VERSION ""

NS_ :

BS_:

BU_: XXX

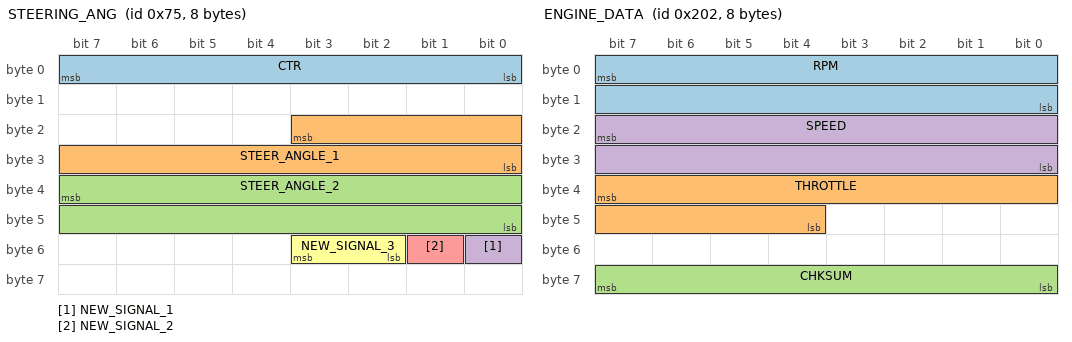
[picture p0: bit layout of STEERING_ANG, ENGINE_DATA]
BO_ 117 STEERING_ANG: 8 XXX
 SG_ CTR : 7|8@0+ (1,0) [0|255] "" XXX
 SG_ STEER_ANGLE_1 : 19|12@0+ (1,0) [0|255] "" XXX
 SG_ STEER_ANGLE_2 : 39|16@0+ (1,0) [0|131071] "" XXX
 SG_ NEW_SIGNAL_1 : 48|1@0+ (1,0) [0|1] "" XXX
 SG_ NEW_SIGNAL_2 : 49|1@0+ (1,0) [0|1] "" XXX
 SG_ NEW_SIGNAL_3 : 51|2@0+ (1,0) [0|63] "" XXX

BO_ 118 NEW_MSG_2: 8 XXX
 SG_ NEW_SIGNAL_2 : 19|12@0+ (1,0) [0|4095] "" XXX
 SG_ CTR : 7|8@0+ (1,0) [0|127] "" XXX

BO_ 514 ENGINE_DATA: 8 XXX
 SG_ RPM : 7|16@0+ (1,0) [0|65535] "" XXX
 SG_ THROTTLE : 39|12@0+ (1,0) [0|255] "" XXX
 SG_ CHKSUM : 56|8@1+ (1,0) [0|127] "" XXX
 SG_ SPEED : 23|16@0+ (0.01,0) [0|32767] "KPH" XXX

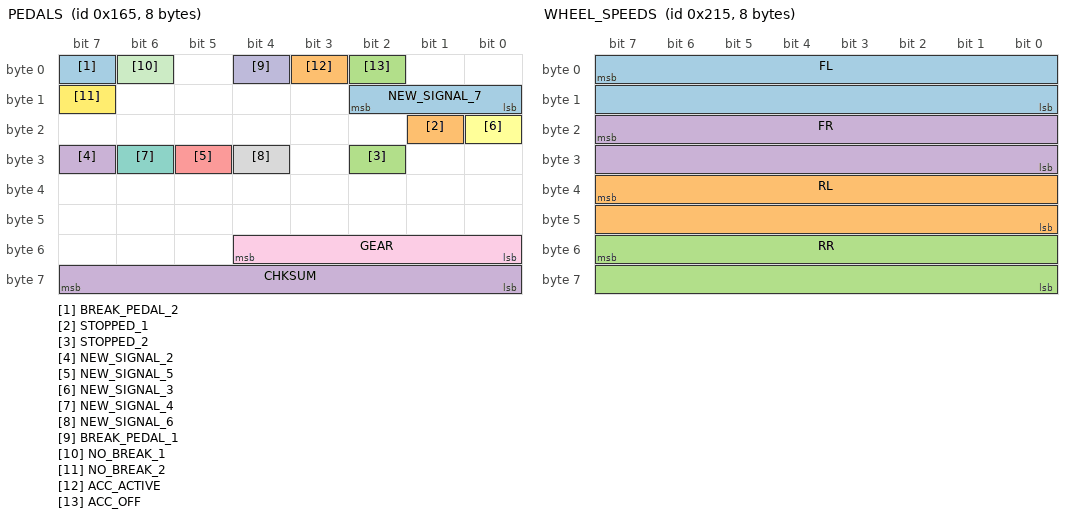
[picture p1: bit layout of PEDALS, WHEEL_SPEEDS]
BO_ 357 PEDALS: 8 XXX
 SG_ BREAK_PEDAL_2 : 7|1@1+ (1,0) [0|255] "" XXX
 SG_ STOPPED_1 : 17|1@0+ (1,0) [0|1] "" XXX
 SG_ STOPPED_2 : 26|1@0+ (1,0) [0|16777215] "" XXX
 SG_ NEW_SIGNAL_2 : 31|1@0+ (1,0) [0|15] "" XXX
 SG_ NEW_SIGNAL_5 : 29|1@0+ (1,0) [0|1] "" XXX
 SG_ NEW_SIGNAL_3 : 16|1@0+ (1,0) [0|3] "" XXX
 SG_ NEW_SIGNAL_4 : 30|1@0+ (1,0) [0|7] "" XXX
 SG_ NEW_SIGNAL_6 : 28|1@0+ (1,0) [0|1] "" XXX
 SG_ GEAR : 48|5@1+ (1,0) [0|255] "" XXX
 SG_ BREAK_PEDAL_1 : 4|1@0+ (1,0) [0|1] "" XXX
 SG_ NO_BREAK_1 : 6|1@0+ (1,0) [0|7] "" XXX
 SG_ NO_BREAK_2 : 15|1@0+ (1,0) [0|7] "" XXX
 SG_ NEW_SIGNAL_7 : 8|3@1+ (1,0) [0|7] "" XXX
 SG_ ACC_ACTIVE : 3|1@0+ (1,0) [0|1] "" XXX
 SG_ ACC_OFF : 2|1@1+ (1,0) [0|15] "" XXX
 SG_ CHKSUM : 63|8@0+ (1,0) [0|15] "" XXX

BO_ 533 WHEEL_SPEEDS: 8 XXX
 SG_ FL : 7|16@0+ (0.01,-100) [0|16383] "" XXX
 SG_ RL : 39|16@0+ (0.01,-100) [0|15] "" XXX
 SG_ RR : 55|16@0+ (0.01,-100) [0|65535] "" XXX
 SG_ FR : 23|16@0+ (0.01,-100) [0|65535] "" XXX

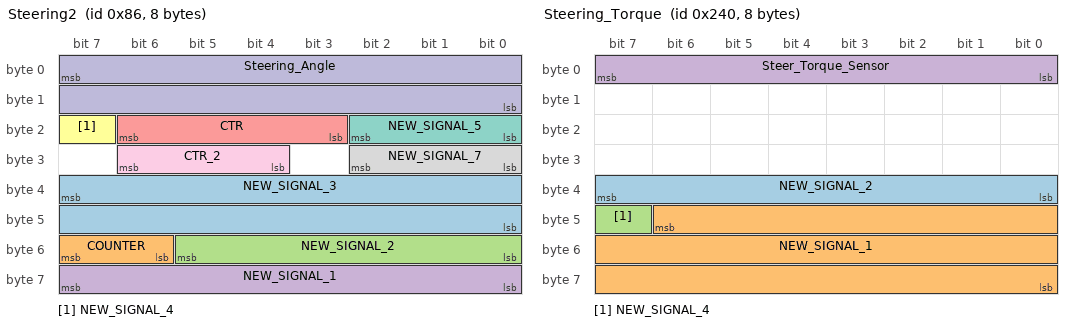
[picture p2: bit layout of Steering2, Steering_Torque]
BO_ 134 Steering2: 8 XXX
 SG_ NEW_SIGNAL_3 : 39|16@0+ (1,0) [0|15] "" XXX
 SG_ COUNTER : 55|2@0+ (1,0) [0|255] "" XXX
 SG_ NEW_SIGNAL_2 : 48|6@1+ (1,0) [0|7] "" XXX
 SG_ NEW_SIGNAL_1 : 63|8@0+ (1,0) [0|255] "" XXX
 SG_ CTR : 22|4@0+ (1,0) [0|7] "" XXX
 SG_ NEW_SIGNAL_4 : 23|1@0+ (1,0) [0|1] "" XXX
 SG_ NEW_SIGNAL_5 : 18|3@0+ (1,0) [0|1] "" XXX
 SG_ NEW_SIGNAL_7 : 24|3@1+ (1,0) [0|7] "" XXX
 SG_ CTR_2 : 28|3@1+ (1,0) [0|7] "" XXX
 SG_ Steering_Angle : 7|16@0+ (0.1,-1600) [-500|500] "deg" XXX

BO_ 576 Steering_Torque: 8 XXX
 SG_ NEW_SIGNAL_2 : 39|8@0+ (1,0) [0|127] "" XXX
 SG_ NEW_SIGNAL_1 : 46|23@0- (1,0) [0|255] "" XXX
 SG_ NEW_SIGNAL_4 : 47|1@0+ (1,0) [0|3] "" XXX
 SG_ Steer_Torque_Sensor : 0|8@1+ (1,0) [0|255] "" XXX

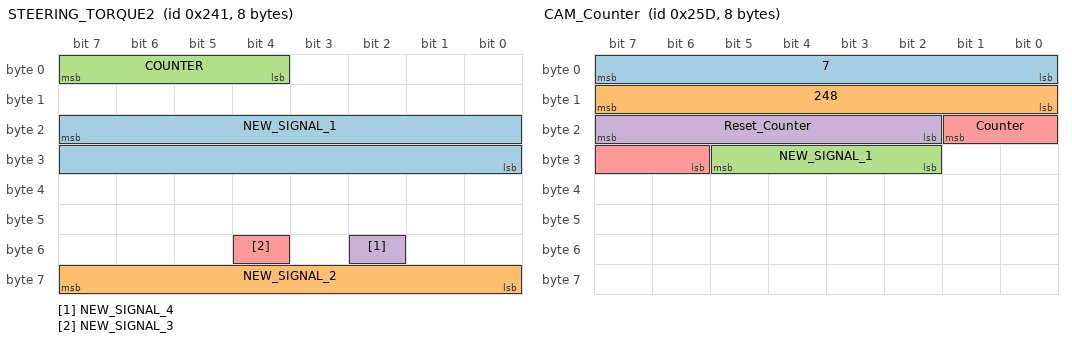
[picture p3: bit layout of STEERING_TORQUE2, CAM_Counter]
BO_ 577 STEERING_TORQUE2: 8 XXX
 SG_ NEW_SIGNAL_1 : 23|16@0+ (1,0) [0|1] "" XXX
 SG_ NEW_SIGNAL_2 : 63|8@0+ (1,0) [0|255] "" XXX
 SG_ COUNTER : 7|4@0+ (1,0) [0|15] "" XXX
 SG_ NEW_SIGNAL_4 : 50|1@1+ (1,0) [0|3] "" XXX
 SG_ NEW_SIGNAL_3 : 52|1@0+ (1,0) [0|3] "" XXX

BO_ 582 CAM__LANEINFO: 8 XXX
 SG_ Counter : 7|2@0+ (1,0) [0|3] "" XXX
 SG_ NEW_SIGNAL_4 : 40|8@1+ (1,0) [0|127] "" XXX
 SG_ NEW_SIGNAL_2 : 55|18@0+ (1,0) [0|65535] "" XXX
 SG_ NEW_SIGNAL_1 : 5|38@0- (1,0) [0|65535] "" XXX

BO_ 541 CAM__Empty: 8 XXX

BO_ 605 CAM_Counter: 8 XXX
 SG_ 7 : 0|8@1+ (1,0) [0|7] "" XXX
 SG_ 248 : 8|8@1+ (1,0) [0|255] "" XXX
 SG_ NEW_SIGNAL_1 : 26|4@1+ (1,0) [0|31] "" XXX
 SG_ Reset_Counter : 23|6@0+ (1,0) [0|63] "" XXX
 SG_ Counter : 17|4@0+ (1,0) [0|255] "" XXX

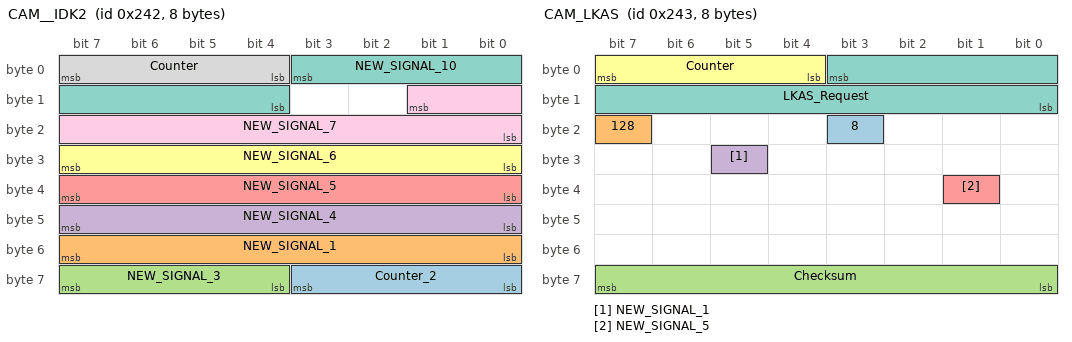
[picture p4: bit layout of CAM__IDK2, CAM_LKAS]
BO_ 578 CAM__IDK2: 8 XXX
 SG_ Counter_2 : 56|4@1+ (1,0) [0|15] "" XXX
 SG_ NEW_SIGNAL_1 : 48|8@1+ (1,0) [0|255] "" XXX
 SG_ NEW_SIGNAL_3 : 63|4@0+ (1,0) [0|255] "" XXX
 SG_ NEW_SIGNAL_4 : 40|8@1+ (1,0) [0|255] "" XXX
 SG_ NEW_SIGNAL_5 : 32|8@1+ (1,0) [0|255] "" XXX
 SG_ NEW_SIGNAL_6 : 24|8@1+ (1,0) [0|255] "" XXX
 SG_ NEW_SIGNAL_10 : 3|8@0+ (1,0) [0|1] "" XXX
 SG_ Counter : 7|4@0+ (1,0) [0|15] "" XXX
 SG_ NEW_SIGNAL_7 : 9|10@0+ (1,0) [0|255] "" XXX

BO_ 579 CAM_LKAS: 8 XXX
 SG_ 8 : 19|1@1+ (1,0) [0|8589934591] "" XXX
 SG_ 128 : 23|1@0+ (1,0) [0|3] "" XXX
 SG_ Checksum : 56|8@1+ (1,0) [0|15] "" XXX
 SG_ NEW_SIGNAL_1 : 29|1@0+ (1,0) [0|65535] "" XXX
 SG_ NEW_SIGNAL_5 : 33|1@1+ (1,0) [0|7] "" XXX
 SG_ Counter : 7|4@0+ (1,0) [0|3] "" XXX
 SG_ LKAS_Request : 3|12@0+ (1,-2048) [0|15] "" XXX

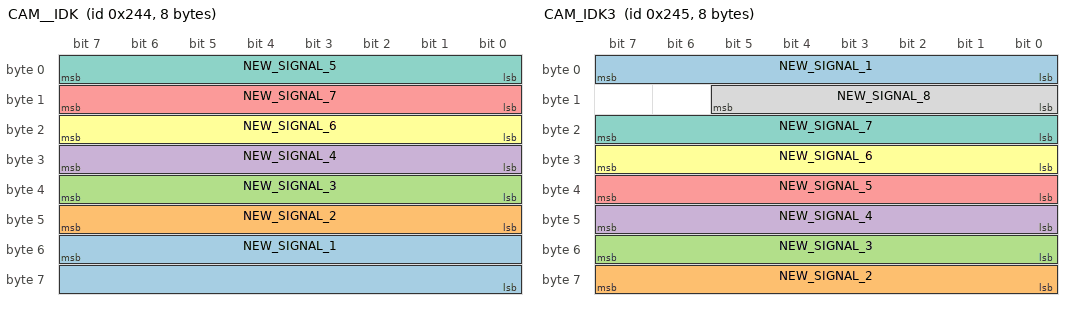
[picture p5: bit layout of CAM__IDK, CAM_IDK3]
BO_ 580 CAM__IDK: 8 XXX
 SG_ NEW_SIGNAL_1 : 55|16@0+ (1,0) [0|255] "" XXX
 SG_ NEW_SIGNAL_2 : 47|8@0+ (1,0) [0|65535] "" XXX
 SG_ NEW_SIGNAL_3 : 32|8@1+ (1,0) [0|255] "" XXX
 SG_ NEW_SIGNAL_4 : 24|8@1+ (1,0) [0|31] "" XXX
 SG_ NEW_SIGNAL_7 : 15|8@0+ (1,0) [0|1] "" XXX
 SG_ NEW_SIGNAL_6 : 16|8@1+ (1,0) [0|3] "" XXX
 SG_ NEW_SIGNAL_5 : 0|8@1+ (1,0) [0|127] "" XXX

BO_ 581 CAM_IDK3: 8 XXX
 SG_ NEW_SIGNAL_1 : 0|8@1+ (1,0) [0|15] "" XXX
 SG_ NEW_SIGNAL_2 : 56|8@1+ (1,0) [0|255] "" XXX
 SG_ NEW_SIGNAL_3 : 48|8@1+ (1,0) [0|255] "" XXX
 SG_ NEW_SIGNAL_4 : 40|8@1+ (1,0) [0|3] "" XXX
 SG_ NEW_SIGNAL_5 : 32|8@1+ (1,0) [0|255] "" XXX
 SG_ NEW_SIGNAL_6 : 24|8@1+ (1,0) [0|255] "" XXX
 SG_ NEW_SIGNAL_7 : 16|8@1+ (1,0) [0|15] "" XXX
 SG_ NEW_SIGNAL_8 : 8|6@1+ (1,0) [0|255] "" XXX

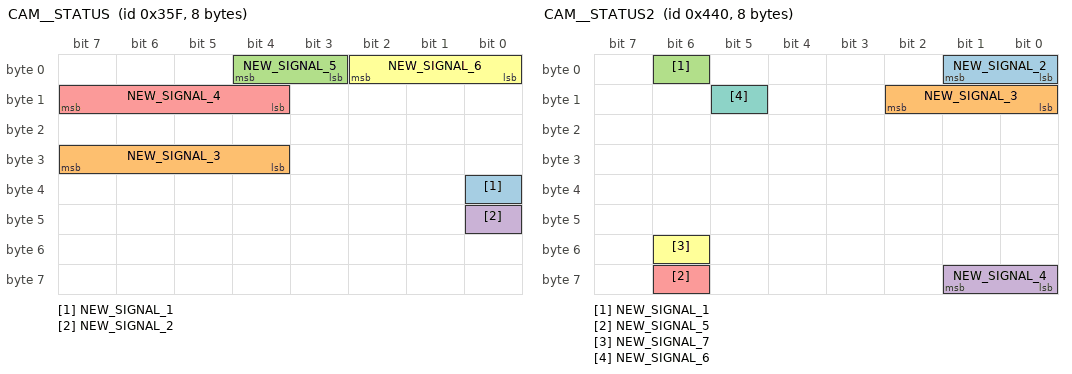
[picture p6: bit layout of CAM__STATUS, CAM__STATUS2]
BO_ 863 CAM__STATUS: 8 XXX
 SG_ NEW_SIGNAL_1 : 32|1@0+ (1,0) [0|32767] "" XXX
 SG_ NEW_SIGNAL_3 : 31|4@0+ (1,0) [0|1] "" XXX
 SG_ NEW_SIGNAL_5 : 4|2@0+ (1,0) [0|32767] "" XXX
 SG_ NEW_SIGNAL_2 : 40|1@1+ (1,0) [0|7] "" XXX
 SG_ NEW_SIGNAL_4 : 15|4@0+ (1,0) [0|15] "" XXX
 SG_ NEW_SIGNAL_6 : 0|3@1+ (1,0) [0|7] "" XXX

BO_ 1157 CAM__Empty2: 8 XXX

BO_ 1160 CAM__Empty3: 8 XXX
 SG_ NEW_SIGNAL_1 : 47|24@0+ (1,0) [0|16777215] "" XXX

BO_ 1088 CAM__STATUS2: 8 XXX
 SG_ NEW_SIGNAL_2 : 0|2@1+ (1,0) [0|3] "" XXX
 SG_ NEW_SIGNAL_3 : 8|3@1+ (1,0) [0|3] "" XXX
 SG_ NEW_SIGNAL_1 : 6|1@0+ (1,0) [0|65535] "" XXX
 SG_ NEW_SIGNAL_4 : 57|2@0+ (1,0) [0|3] "" XXX
 SG_ NEW_SIGNAL_5 : 62|1@0+ (1,0) [0|3] "" XXX
 SG_ NEW_SIGNAL_7 : 54|1@0+ (1,0) [0|31] "" XXX
 SG_ NEW_SIGNAL_6 : 13|1@0+ (1,0) [0|15] "" XXX

BO_ 1479 NEW_MSG_470: 8 XXX

BO_ 1456 NEW_MSG_300: 8 XXX

BO_ 1446 NEW_MSG_a600: 8 XXX

BO_ 1416 NEW_MSG_0800: 8 XXX

BO_ 1086 NEW_MSG_6: 8 XXX
 SG_ NEW_SIGNAL_1 : 8|4@1+ (1,0) [0|3] "" XXX
 SG_ NEW_SIGNAL_2 : 16|4@1+ (1,0) [0|15] "" XXX

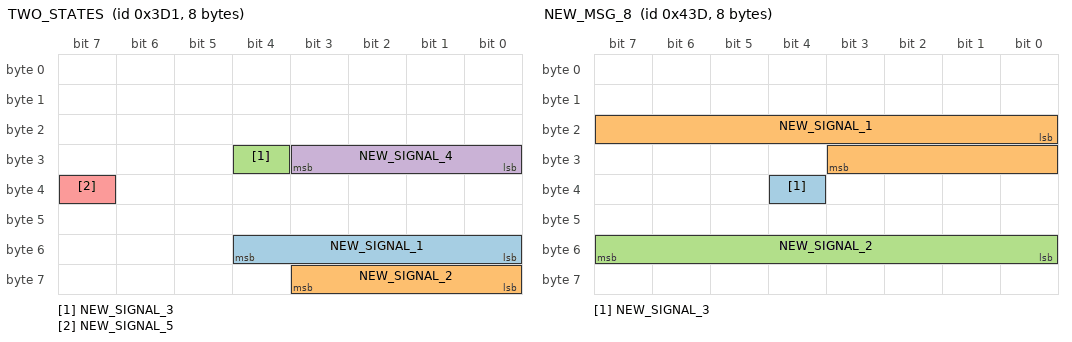
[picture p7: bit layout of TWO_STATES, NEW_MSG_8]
BO_ 977 TWO_STATES: 8 XXX
 SG_ NEW_SIGNAL_1 : 48|5@1+ (1,0) [0|7] "" XXX
 SG_ NEW_SIGNAL_2 : 56|4@1+ (1,0) [0|7] "" XXX
 SG_ NEW_SIGNAL_3 : 28|1@0+ (1,0) [0|255] "" XXX
 SG_ NEW_SIGNAL_4 : 24|4@1+ (1,0) [0|3] "" XXX
 SG_ NEW_SIGNAL_5 : 39|1@0+ (1,0) [0|1] "" XXX

BO_ 1085 NEW_MSG_8: 8 XXX
 SG_ NEW_SIGNAL_3 : 36|1@0+ (1,0) [0|255] "" XXX
 SG_ NEW_SIGNAL_1 : 16|12@1+ (1,0) [0|15] "" XXX
 SG_ NEW_SIGNAL_2 : 48|8@1+ (1,0) [0|65535] "" XXX

BO_ 159 NEW_MSG_9: 8 XXX
 SG_ NEW_SIGNAL_1 : 50|4@1+ (1,0) [0|15] "" XXX

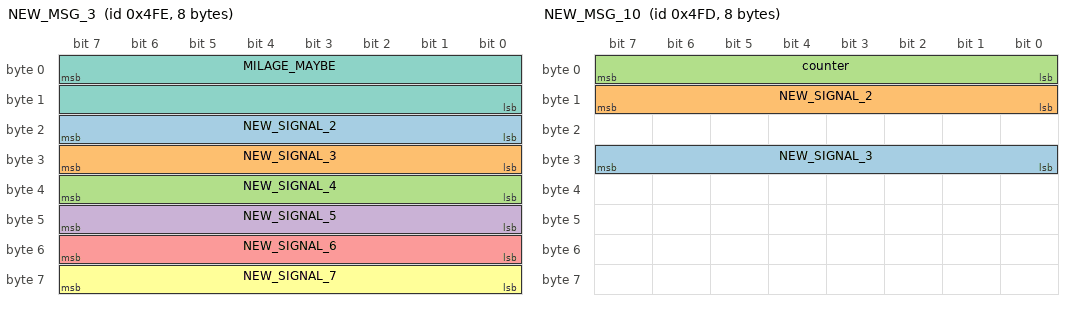
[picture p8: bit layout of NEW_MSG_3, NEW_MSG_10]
BO_ 1278 NEW_MSG_3: 8 XXX
 SG_ NEW_SIGNAL_2 : 23|8@0+ (1,0) [0|255] "" XXX
 SG_ NEW_SIGNAL_3 : 31|8@0+ (1,0) [0|255] "" XXX
 SG_ NEW_SIGNAL_4 : 39|8@0+ (1,0) [0|255] "" XXX
 SG_ NEW_SIGNAL_5 : 47|8@0+ (1,0) [0|255] "" XXX
 SG_ NEW_SIGNAL_6 : 55|8@0+ (1,0) [0|255] "" XXX
 SG_ NEW_SIGNAL_7 : 63|8@0+ (1,0) [0|255] "" XXX
 SG_ MILAGE_MAYBE : 7|16@0+ (1,0) [0|255] "" XXX

BO_ 1277 NEW_MSG_10: 8 XXX
 SG_ NEW_SIGNAL_3 : 31|8@0+ (1,0) [0|255] "" XXX
 SG_ NEW_SIGNAL_2 : 15|8@0+ (1,0) [0|255] "" XXX
 SG_ counter : 7|8@0+ (1,0) [0|255] "" XXX

BO_ 1275 NEW_MSG_11: 8 XXX
 SG_ counter : 7|8@0+ (1,0) [0|255] "" XXX

BO_ 1274 NEW_MSG_12: 8 XXX
 SG_ NEW_SIGNAL_1 : 24|2@1+ (1,0) [0|15] "" XXX

BO_ 1180 last_byte_roughRPM: 8 XXX
 SG_ NEW_SIGNAL_1 : 63|8@0+ (1,0) [0|255] "" XXX

BO_ 1078 Bit_Pulse: 8 XXX
 SG_ NEW_SIGNAL_1 : 2|1@0+ (1,0) [0|1] "" XXX

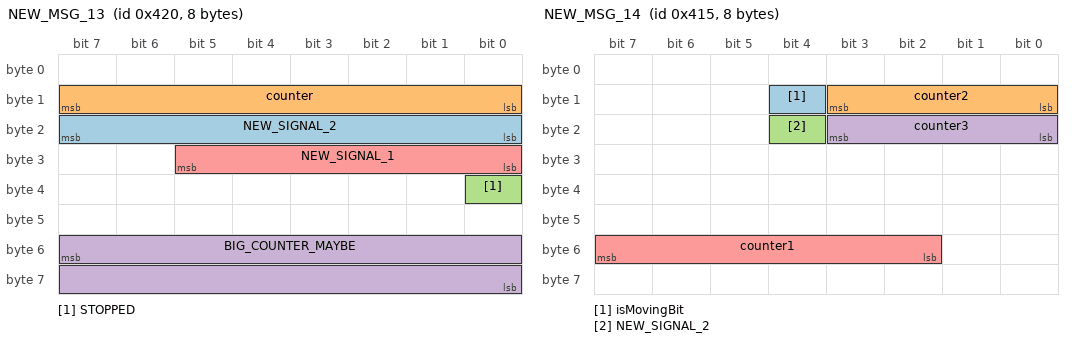
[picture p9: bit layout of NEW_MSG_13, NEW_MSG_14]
BO_ 1056 NEW_MSG_13: 8 XXX
 SG_ NEW_SIGNAL_2 : 23|8@0+ (1,0) [0|255] "" XXX
 SG_ counter : 15|8@0+ (1,0) [0|255] "" XXX
 SG_ STOPPED : 32|1@0+ (1,0) [0|255] "" XXX
 SG_ BIG_COUNTER_MAYBE : 55|16@0+ (1,0) [0|255] "" XXX
 SG_ NEW_SIGNAL_1 : 29|6@0+ (1,0) [0|255] "" XXX

BO_ 1045 NEW_MSG_14: 8 XXX
 SG_ isMovingBit : 12|1@0+ (1,0) [0|3] "" XXX
 SG_ counter2 : 8|4@1+ (1,0) [0|15] "" XXX
 SG_ NEW_SIGNAL_2 : 20|1@0+ (1,0) [0|3] "" XXX
 SG_ counter3 : 19|4@0+ (1,0) [0|31] "" XXX
 SG_ counter1 : 55|6@0+ (1,0) [0|63] "" XXX

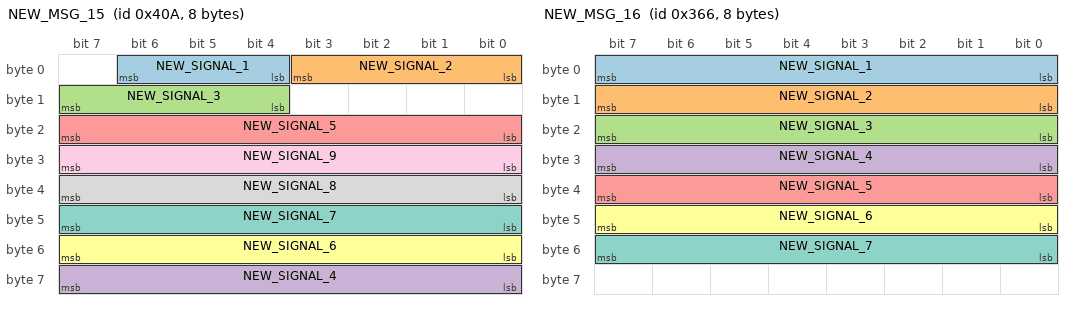
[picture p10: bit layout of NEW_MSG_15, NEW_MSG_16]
BO_ 1034 NEW_MSG_15: 8 XXX
 SG_ NEW_SIGNAL_1 : 6|3@0+ (1,0) [0|3] "" XXX
 SG_ NEW_SIGNAL_2 : 0|4@1+ (1,0) [0|3] "" XXX
 SG_ NEW_SIGNAL_3 : 15|4@0+ (1,0) [0|15] "" XXX
 SG_ NEW_SIGNAL_4 : 63|8@0+ (1,0) [0|255] "" XXX
 SG_ NEW_SIGNAL_5 : 23|8@0+ (1,0) [0|255] "" XXX
 SG_ NEW_SIGNAL_6 : 55|8@0+ (1,0) [0|255] "" XXX
 SG_ NEW_SIGNAL_7 : 47|8@0+ (1,0) [0|255] "" XXX
 SG_ NEW_SIGNAL_8 : 39|8@0+ (1,0) [0|255] "" XXX
 SG_ NEW_SIGNAL_9 : 31|8@0+ (1,0) [0|255] "" XXX

BO_ 870 NEW_MSG_16: 8 XXX
 SG_ NEW_SIGNAL_1 : 7|8@0+ (1,0) [0|255] "" XXX
 SG_ NEW_SIGNAL_2 : 15|8@0+ (1,0) [0|255] "" XXX
 SG_ NEW_SIGNAL_3 : 23|8@0+ (1,0) [0|255] "" XXX
 SG_ NEW_SIGNAL_4 : 31|8@0+ (1,0) [0|255] "" XXX
 SG_ NEW_SIGNAL_5 : 39|8@0+ (1,0) [0|255] "" XXX
 SG_ NEW_SIGNAL_6 : 47|8@0+ (1,0) [0|255] "" XXX
 SG_ NEW_SIGNAL_7 : 55|8@0+ (1,0) [0|255] "" XXX

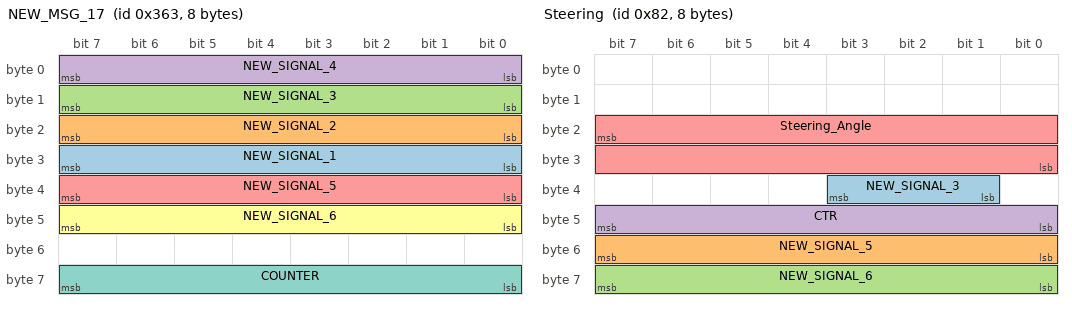
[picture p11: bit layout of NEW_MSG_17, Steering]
BO_ 867 NEW_MSG_17: 8 XXX
 SG_ NEW_SIGNAL_1 : 31|8@0+ (1,0) [0|255] "" XXX
 SG_ NEW_SIGNAL_2 : 23|8@0+ (1,0) [0|255] "" XXX
 SG_ NEW_SIGNAL_3 : 15|8@0+ (1,0) [0|255] "" XXX
 SG_ NEW_SIGNAL_4 : 7|8@0+ (1,0) [0|255] "" XXX
 SG_ NEW_SIGNAL_5 : 39|8@0+ (1,0) [0|255] "" XXX
 SG_ NEW_SIGNAL_6 : 47|8@0+ (1,0) [0|255] "" XXX
 SG_ COUNTER : 63|8@0+ (1,0) [0|255] "" XXX

BO_ 130 Steering: 8 XXX
 SG_ NEW_SIGNAL_3 : 35|3@0+ (1,0) [0|255] "" XXX
 SG_ NEW_SIGNAL_5 : 55|8@0+ (1,0) [0|255] "" XXX
 SG_ NEW_SIGNAL_6 : 63|8@0+ (1,0) [0|255] "" XXX
 SG_ CTR : 47|8@0+ (1,0) [0|255] "" XXX
 SG_ Steering_Angle : 23|16@0+ (0.05,-1600) [500|-500] "" XXX

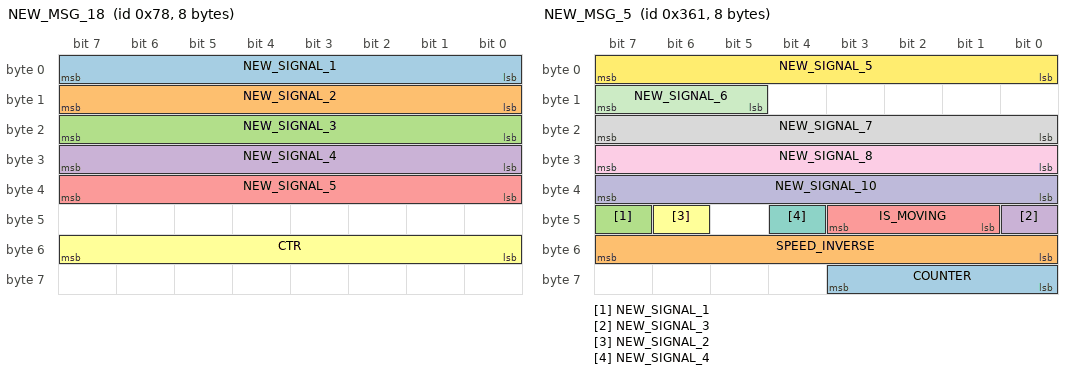
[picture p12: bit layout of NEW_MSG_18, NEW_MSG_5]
BO_ 120 NEW_MSG_18: 8 XXX
 SG_ NEW_SIGNAL_1 : 7|8@0+ (1,0) [0|255] "" XXX
 SG_ NEW_SIGNAL_2 : 15|8@0+ (1,0) [0|255] "" XXX
 SG_ NEW_SIGNAL_3 : 23|8@0+ (1,0) [0|255] "" XXX
 SG_ NEW_SIGNAL_4 : 31|8@0+ (1,0) [0|255] "" XXX
 SG_ NEW_SIGNAL_5 : 39|8@0+ (1,0) [0|255] "" XXX
 SG_ CTR : 55|8@0+ (1,0) [0|255] "" XXX

BO_ 304 NEW_MSGRPM: 8 XXX
 SG_ NEW_SIGNAL_1 : 47|16@0+ (1,0) [0|255] "" XXX

BO_ 865 NEW_MSG_5: 8 XXX
 SG_ COUNTER : 56|4@1+ (1,0) [0|15] "" XXX
 SG_ SPEED_INVERSE : 55|8@0+ (1,0) [0|255] "" XXX
 SG_ NEW_SIGNAL_1 : 47|1@0+ (1,0) [0|255] "" XXX
 SG_ NEW_SIGNAL_3 : 40|1@0+ (1,0) [0|1] "" XXX
 SG_ IS_MOVING : 43|3@0+ (1,0) [0|127] "" XXX
 SG_ NEW_SIGNAL_2 : 46|1@0+ (1,0) [0|7] "" XXX
 SG_ NEW_SIGNAL_4 : 44|1@0+ (1,0) [0|1] "" XXX
 SG_ NEW_SIGNAL_7 : 23|8@0+ (1,0) [0|255] "" XXX
 SG_ NEW_SIGNAL_8 : 31|8@0+ (1,0) [0|255] "" XXX
 SG_ NEW_SIGNAL_10 : 39|8@0+ (1,0) [0|255] "" XXX
 SG_ NEW_SIGNAL_6 : 15|3@0+ (1,0) [0|255] "" XXX
 SG_ NEW_SIGNAL_5 : 7|8@0+ (1,0) [0|255] "" XXX

BO_ 836 NEW_MSG_19: 8 XXX
 SG_ COUNTER1 : 48|4@1+ (1,0) [0|15] "" XXX
 SG_ COUNTER2 : 63|8@0+ (1,0) [0|255] "" XXX

BO_ 832 NEW_MSG_20: 8 XXX
 SG_ NEW_SIGNAL_4 : 8|4@1+ (1,0) [0|3] "" XXX
 SG_ COUNTER2 : 23|4@0+ (1,0) [0|255] "" XXX

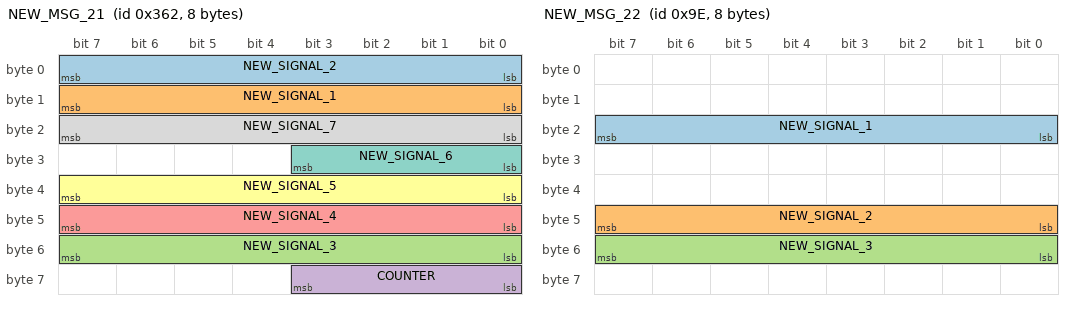
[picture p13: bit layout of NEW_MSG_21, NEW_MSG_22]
BO_ 866 NEW_MSG_21: 8 XXX
 SG_ NEW_SIGNAL_2 : 7|8@0+ (1,0) [0|131071] "" XXX
 SG_ NEW_SIGNAL_1 : 15|8@0+ (1,0) [0|15] "" XXX
 SG_ NEW_SIGNAL_3 : 55|8@0+ (1,0) [0|255] "" XXX
 SG_ COUNTER : 59|4@0+ (1,0) [0|15] "" XXX
 SG_ NEW_SIGNAL_4 : 47|8@0+ (1,0) [0|255] "" XXX
 SG_ NEW_SIGNAL_5 : 39|8@0+ (1,0) [0|255] "" XXX
 SG_ NEW_SIGNAL_6 : 27|4@0+ (1,0) [0|255] "" XXX
 SG_ NEW_SIGNAL_7 : 23|8@0+ (1,0) [0|255] "" XXX

BO_ 158 NEW_MSG_22: 8 XXX
 SG_ NEW_SIGNAL_1 : 23|8@0+ (1,0) [0|15] "" XXX
 SG_ NEW_SIGNAL_2 : 47|8@0+ (1,0) [0|255] "" XXX
 SG_ NEW_SIGNAL_3 : 55|8@0+ (1,0) [0|255] "" XXX

BO_ 157 CRZ_BTNS: 8 XXX
 SG_ COUNTER : 29|2@0+ (1,0) [0|255] "" XXX
 SG_ PULSE_1 : 27|1@1+ (1,0) [0|1] "" XXX
 SG_ SET_P_INV : 21|1@0+ (1,0) [0|3] "" XXX
 SG_ CAN_OFF_INV : 17|1@1+ (1,0) [0|3] "" XXX
 SG_ CAN_OFF : 0|1@1+ (1,0) [0|3] "" XXX
 SG_ SET_M_INV : 22|1@0+ (1,0) [0|255] "" XXX
 SG_ SET_M : 5|1@0+ (1,0) [0|3] "" XXX
 SG_ SET_P : 4|1@0+ (1,0) [0|3] "" XXX
 SG_ RES_INV : 19|1@1+ (1,0) [0|3] "" XXX
 SG_ RES : 2|1@1+ (1,0) [0|3] "" XXX
 SG_ PULSE_2 : 26|1@1+ (1,0) [0|1] "" XXX
 SG_ DISTANCE_LESS : 7|1@0+ (1,0) [0|1] "" XXX
 SG_ DISTANCE_LESS_INV : 8|1@0+ (1,0) [0|31] "" XXX
 SG_ DISTANCE_MORE : 6|1@0+ (1,0) [0|3] "" XXX
 SG_ DISTANCE_MORE_INV : 23|1@0+ (1,0) [0|1] "" XXX
 SG_ MODE_Y : 13|1@1+ (1,0) [0|3] "" XXX
 SG_ MODE_X : 14|1@0+ (1,0) [0|255] "" XXX
 SG_ MODE_Y_INV : 30|1@0+ (1,0) [0|3] "" XXX
 SG_ MODE_X_INV : 31|1@0+ (1,0) [0|3] "" XXX

BO_ 154 BLINK_INFO: 8 XXX
 SG_ LEFT_BLINK : 18|1@1+ (1,0) [0|3] "" XXX
 SG_ RIGHT_BLINK : 19|1@0+ (1,0) [0|255] "" XXX

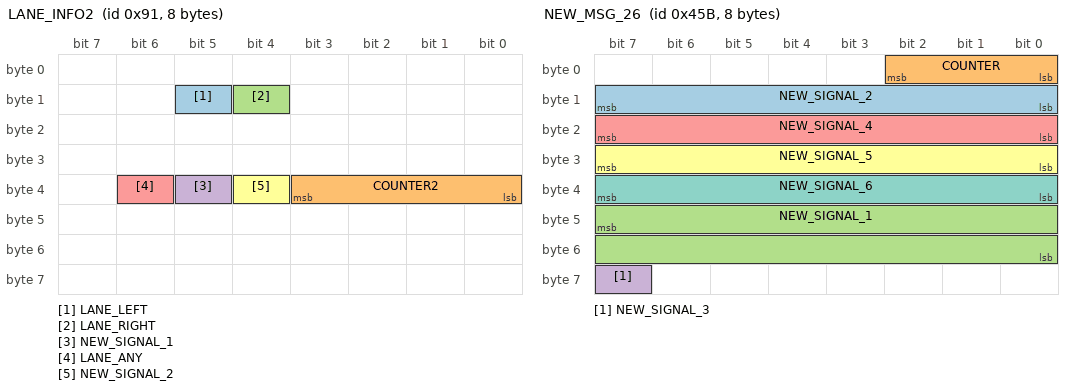
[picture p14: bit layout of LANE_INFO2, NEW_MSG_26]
BO_ 145 LANE_INFO2: 8 XXX
 SG_ LANE_LEFT : 13|1@0+ (1,0) [0|255] "" XXX
 SG_ COUNTER2 : 35|4@0+ (1,0) [0|255] "" XXX
 SG_ LANE_RIGHT : 12|1@1+ (1,0) [0|3] "" XXX
 SG_ NEW_SIGNAL_1 : 37|1@0+ (1,0) [0|3] "" XXX
 SG_ LANE_ANY : 38|1@0+ (1,0) [0|3] "" XXX
 SG_ NEW_SIGNAL_2 : 36|1@0+ (1,0) [0|3] "" XXX

BO_ 80 NEW_MSG_23: 8 XXX

BO_ 978 NEW_MSG_24: 8 XXX

BO_ 607 NEW_MSG_25: 8 XXX

BO_ 1115 NEW_MSG_26: 8 XXX
 SG_ NEW_SIGNAL_2 : 15|8@0+ (1,0) [0|255] "" XXX
 SG_ COUNTER : 2|3@0+ (1,0) [0|255] "" XXX
 SG_ NEW_SIGNAL_1 : 47|16@0+ (1,0) [0|65535] "" XXX
 SG_ NEW_SIGNAL_3 : 63|1@0+ (1,0) [0|1] "" XXX
 SG_ NEW_SIGNAL_4 : 23|8@0+ (1,0) [0|255] "" XXX
 SG_ NEW_SIGNAL_5 : 31|8@0+ (1,0) [0|255] "" XXX
 SG_ NEW_SIGNAL_6 : 39|8@0+ (1,0) [0|255] "" XXX

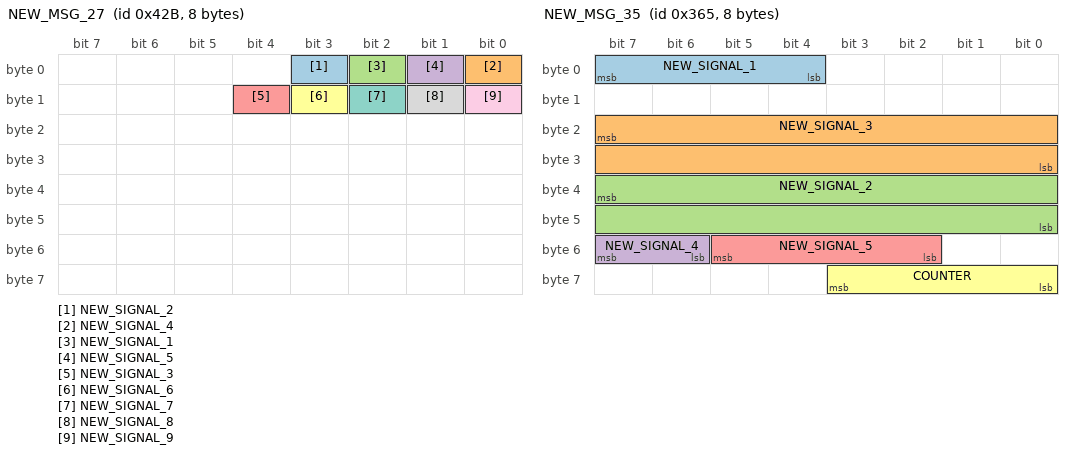
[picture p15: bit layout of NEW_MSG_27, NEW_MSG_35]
BO_ 1067 NEW_MSG_27: 8 XXX
 SG_ NEW_SIGNAL_2 : 3|1@0+ (1,0) [0|1] "" XXX
 SG_ NEW_SIGNAL_4 : 0|1@0+ (1,0) [0|1] "" XXX
 SG_ NEW_SIGNAL_1 : 2|1@0+ (1,0) [0|1] "" XXX
 SG_ NEW_SIGNAL_5 : 1|1@0+ (1,0) [0|1] "" XXX
 SG_ NEW_SIGNAL_3 : 12|1@0+ (1,0) [0|1] "" XXX
 SG_ NEW_SIGNAL_6 : 11|1@1+ (1,0) [0|3] "" XXX
 SG_ NEW_SIGNAL_7 : 10|1@0+ (1,0) [0|1] "" XXX
 SG_ NEW_SIGNAL_8 : 9|1@0+ (1,0) [0|1] "" XXX
 SG_ NEW_SIGNAL_9 : 8|1@0+ (1,0) [0|1] "" XXX

BO_ 358 NEW_MSG_28: 8 XXX

BO_ 608 NEW_MSG_29: 8 XXX
 SG_ NEW_SIGNAL_1 : 8|5@1+ (1,0) [0|7] "" XXX

BO_ 606 SPEED_TBD: 8 XXX
 SG_ SPEED_TBD : 7|12@0+ (1,0) [0|255] "" XXX
 SG_ NEW_SIGNAL_1 : 23|12@0+ (1,0) [0|65535] "" XXX

BO_ 552 NEW_MSG_31: 8 XXX

BO_ 543 CRZ_TBD: 8 XXX
 SG_ NEW_SIGNAL_3 : 34|1@0+ (1,0) [0|1] "" XXX
 SG_ CHKSUM : 63|8@0+ (1,0) [0|15] "" XXX
 SG_ COUNTER : 51|4@0+ (1,0) [0|15] "" XXX
 SG_ NEW_SIGNAL_1 : 55|4@0+ (1,0) [0|15] "" XXX
 SG_ NEW_SIGNAL_4 : 43|4@0+ (1,0) [0|255] "" XXX
 SG_ NEW_SIGNAL_5 : 47|4@0+ (1,0) [0|15] "" XXX
 SG_ NEW_SIGNAL_6 : 6|1@0+ (1,0) [0|255] "" XXX
 SG_ NEW_SIGNAL_8 : 0|1@0+ (1,0) [0|31] "" XXX
 SG_ NEW_SIGNAL_9 : 1|1@0+ (1,0) [0|1] "" XXX
 SG_ NEW_SIGNAL_10 : 2|1@0+ (1,0) [0|1] "" XXX
 SG_ NEW_SIGNAL_12 : 10|1@0+ (1,0) [0|1] "" XXX
 SG_ NEW_SIGNAL_13 : 9|1@0+ (1,0) [0|1] "" XXX
 SG_ NEW_SIGNAL_18 : 12|1@0+ (1,0) [0|15] "" XXX
 SG_ NEW_SIGNAL_19 : 14|1@0+ (1,0) [0|1] "" XXX
 SG_ NEW_SIGNAL_20 : 15|1@0+ (1,0) [0|1] "" XXX
 SG_ NEW_SIGNAL_21 : 23|1@0+ (1,0) [0|15] "" XXX
 SG_ NEW_SIGNAL_24 : 31|1@0+ (1,0) [0|1] "" XXX
 SG_ GAS_PEDAL_PRESSED : 32|1@0+ (1,0) [0|255] "" XXX
 SG_ CRZ_STARTED : 18|1@0+ (1,0) [0|1] "" XXX
 SG_ PLUS_ONE_CRZ : 17|1@0+ (1,0) [0|255] "" XXX
 SG_ PLUS_ONE_CRZ_2 : 19|1@0+ (1,0) [0|1] "" XXX
 SG_ GAS_MAYBE : 22|1@0+ (1,0) [0|1] "" XXX
 SG_ NONACC_ACTIVE : 5|1@0+ (1,0) [0|1] "" XXX
 SG_ NONACC_RELATED : 11|1@0+ (1,0) [0|255] "" XXX
 SG_ CRUISE_ACTIVE_CAR_MOVING : 16|1@0+ (1,0) [0|1] "" XXX
 SG_ CAS_CMD_MAYBE : 30|7@0+ (1,0) [0|255] "" XXX

BO_ 542 NEW_MSG_33: 8 XXX
 SG_ COUNTER2 : 56|4@1+ (1,0) [0|15] "" XXX
 SG_ COUNTER : 48|4@1+ (1,0) [0|15] "" XXX

BO_ 868 NEW_MSG_34: 8 XXX
 SG_ COUNTER : 59|4@0+ (1,0) [0|255] "" XXX

BO_ 869 NEW_MSG_35: 8 XXX
 SG_ NEW_SIGNAL_1 : 7|4@0+ (1,0) [0|255] "" XXX
 SG_ NEW_SIGNAL_3 : 23|16@0+ (1,0) [0|255] "" XXX
 SG_ NEW_SIGNAL_2 : 39|16@0+ (1,0) [0|255] "" XXX
 SG_ NEW_SIGNAL_4 : 55|2@0+ (1,0) [0|255] "" XXX
 SG_ NEW_SIGNAL_5 : 50|4@1+ (1,0) [0|15] "" XXX
 SG_ COUNTER : 59|4@0+ (1,0) [0|255] "" XXX

BO_ 1114 NEW_MSG_4: 8 XXX

BO_ 535 CURVE_CTRS: 8 XXX
 SG_ CTR_A_1 : 4|3@0+ (1,0) [0|31] "" XXX
 SG_ CTR_A_2 : 7|3@0+ (1,0) [0|255] "" XXX
 SG_ CTR_B_1 : 12|3@0+ (1,0) [0|7] "" XXX
 SG_ CTR_B_2 : 15|3@0+ (1,0) [0|7] "" XXX
 SG_ CTR_C_1 : 20|3@0+ (1,0) [0|7] "" XXX
 SG_ CTR_C_2 : 23|3@0+ (1,0) [0|255] "" XXX
 SG_ CTR_D_2 : 31|3@0+ (1,0) [0|7] "" XXX
 SG_ CTR_D_1 : 28|3@0+ (1,0) [0|7] "" XXX
 SG_ CURVE : 39|16@0+ (1,0) [0|7] "" XXX
 SG_ CTR : 55|8@0+ (1,0) [0|255] "" XXX
 SG_ CHK_MAYBE : 63|8@0+ (1,0) [0|255] "" XXX
 SG_ NEW_SIGNAL_1 : 0|1@0+ (1,0) [0|1] "" XXX
 SG_ NEW_SIGNAL_2 : 1|1@0+ (1,0) [0|1] "" XXX
 SG_ NEW_SIGNAL_3 : 8|1@0+ (1,0) [0|1] "" XXX
 SG_ NEW_SIGNAL_4 : 9|1@0+ (1,0) [0|1] "" XXX
 SG_ NEW_SIGNAL_5 : 16|1@0+ (1,0) [0|1] "" XXX
 SG_ NEW_SIGNAL_6 : 17|1@0+ (1,0) [0|1] "" XXX
 SG_ NEW_SIGNAL_7 : 24|1@0+ (1,0) [0|1] "" XXX
 SG_ NEW_SIGNAL_8 : 25|1@0+ (1,0) [0|1] "" XXX

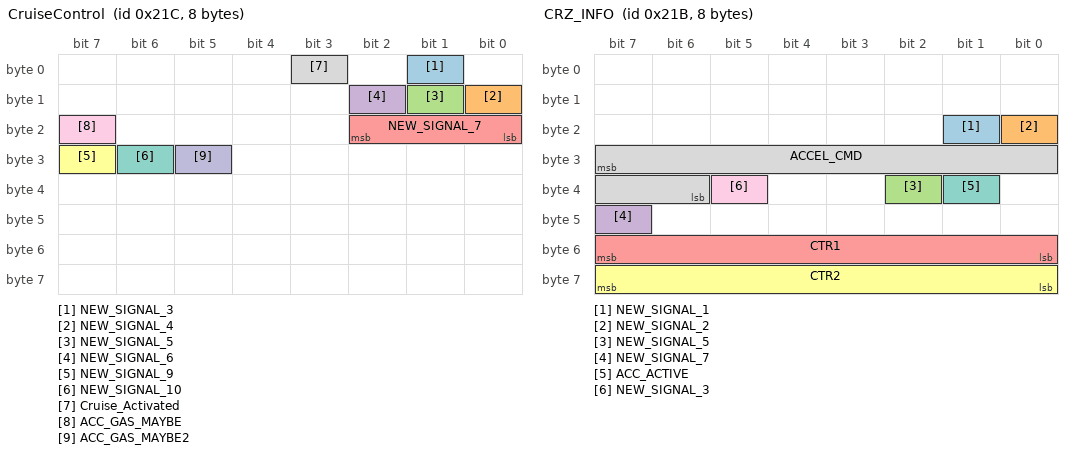
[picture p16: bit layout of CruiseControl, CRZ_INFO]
BO_ 540 CruiseControl: 8 XXX
 SG_ NEW_SIGNAL_3 : 1|1@0+ (1,0) [0|1] "" XXX
 SG_ NEW_SIGNAL_4 : 8|1@0+ (1,0) [0|255] "" XXX
 SG_ NEW_SIGNAL_5 : 9|1@0+ (1,0) [0|1] "" XXX
 SG_ NEW_SIGNAL_6 : 10|1@0+ (1,0) [0|1] "" XXX
 SG_ NEW_SIGNAL_7 : 18|3@0+ (1,0) [0|255] "" XXX
 SG_ NEW_SIGNAL_9 : 31|1@0+ (1,0) [0|255] "" XXX
 SG_ NEW_SIGNAL_10 : 30|1@0+ (1,0) [0|1] "" XXX
 SG_ Cruise_Activated : 3|1@0+ (1,0) [0|1] "" XXX
 SG_ ACC_GAS_MAYBE : 23|1@0+ (1,0) [0|31] "" XXX
 SG_ ACC_GAS_MAYBE2 : 29|1@0+ (1,0) [0|1] "" XXX

BO_ 539 CRZ_INFO: 8 XXX
 SG_ NEW_SIGNAL_1 : 17|1@0+ (1,0) [0|255] "" XXX
 SG_ NEW_SIGNAL_2 : 16|1@0+ (1,0) [0|1] "" XXX
 SG_ NEW_SIGNAL_5 : 34|1@0+ (1,0) [0|1] "" XXX
 SG_ NEW_SIGNAL_7 : 47|1@0+ (1,0) [0|255] "" XXX
 SG_ CTR1 : 55|8@0+ (1,0) [0|255] "" XXX
 SG_ CTR2 : 63|8@0+ (1,0) [0|255] "" XXX
 SG_ ACC_ACTIVE : 33|1@0+ (1,0) [0|1] "" XXX
 SG_ ACCEL_CMD : 31|10@0+ (1,0) [0|1] "" XXX
 SG_ NEW_SIGNAL_3 : 37|1@0+ (1,0) [0|255] "" XXX

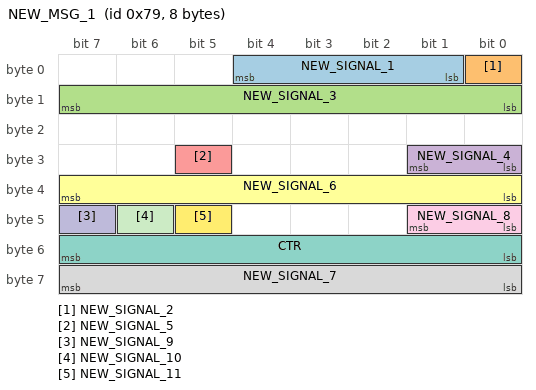
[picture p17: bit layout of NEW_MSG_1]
BO_ 121 NEW_MSG_1: 8 XXX
 SG_ NEW_SIGNAL_1 : 4|4@0+ (1,0) [0|255] "" XXX
 SG_ NEW_SIGNAL_2 : 0|1@0+ (1,0) [0|1] "" XXX
 SG_ NEW_SIGNAL_3 : 15|8@0+ (1,0) [0|255] "" XXX
 SG_ NEW_SIGNAL_4 : 25|2@0+ (1,0) [0|255] "" XXX
 SG_ NEW_SIGNAL_5 : 29|1@0+ (1,0) [0|15] "" XXX
 SG_ NEW_SIGNAL_6 : 39|8@0+ (1,0) [0|255] "" XXX
 SG_ CTR : 55|8@0+ (1,0) [0|255] "" XXX
 SG_ NEW_SIGNAL_7 : 63|8@0+ (1,0) [0|255] "" XXX
 SG_ NEW_SIGNAL_8 : 41|2@0+ (1,0) [0|255] "" XXX
 SG_ NEW_SIGNAL_9 : 47|1@0+ (1,0) [0|63] "" XXX
 SG_ NEW_SIGNAL_10 : 46|1@0+ (1,0) [0|1] "" XXX
 SG_ NEW_SIGNAL_11 : 45|1@0+ (1,0) [0|1] "" XXX

CM_ SG_ 157 CAN_OFF "Disengage Cruise if enabled, if already disabled  TURN it OFF ";
